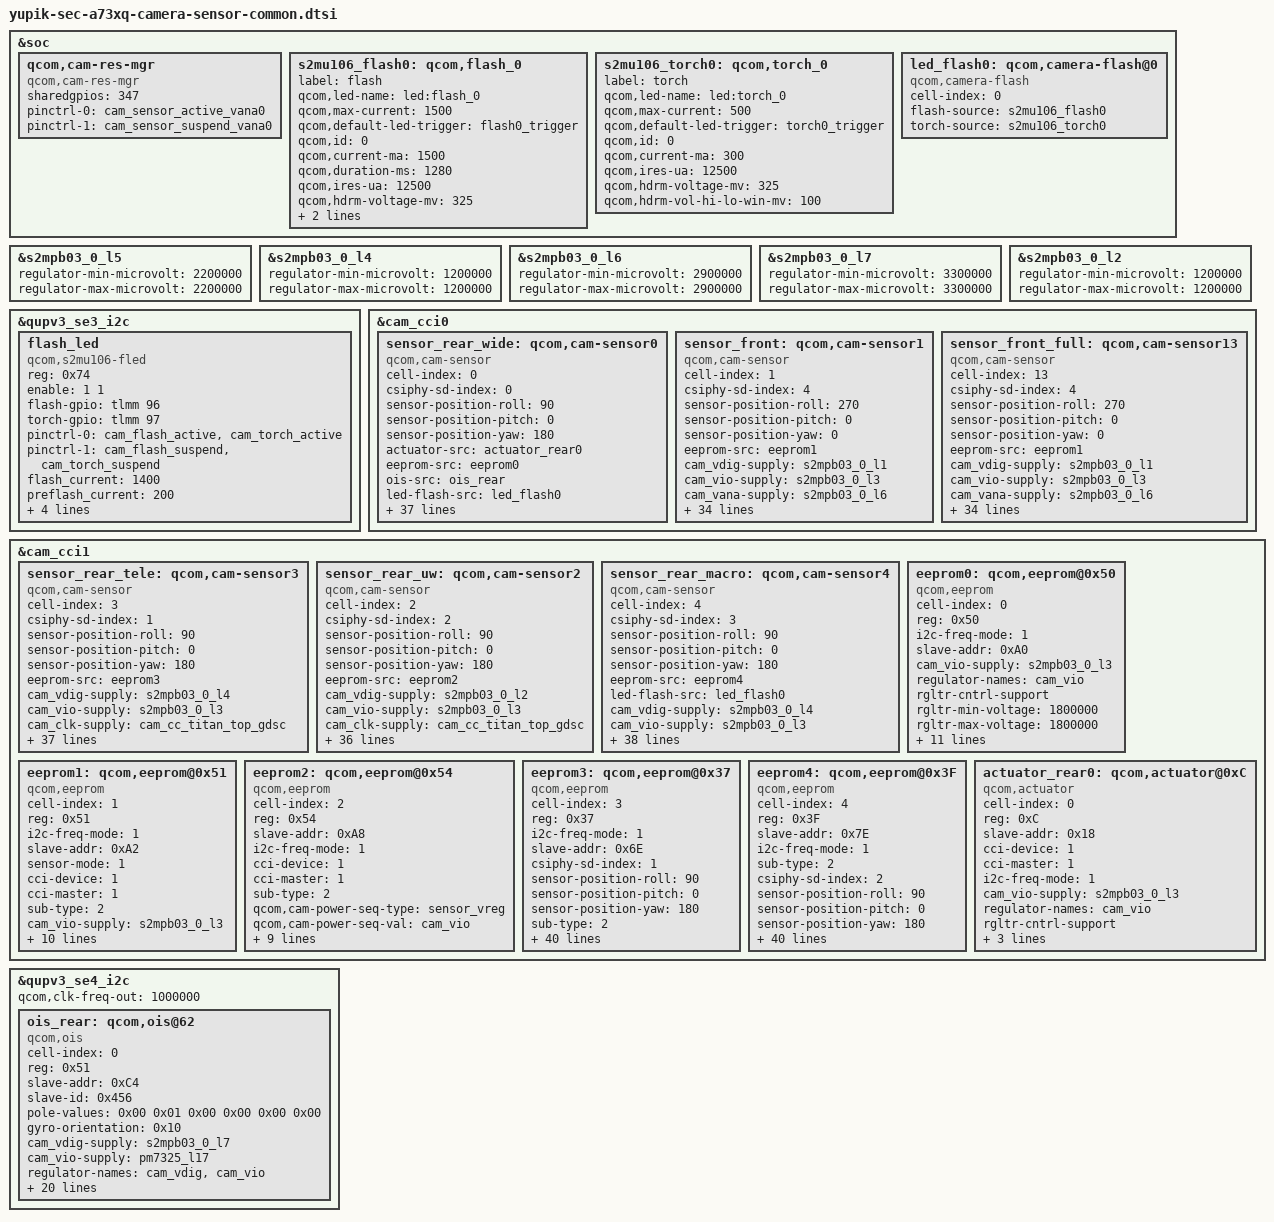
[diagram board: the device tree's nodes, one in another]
/*
 * Copyright (c) 2019, The Linux Foundation. All rights reserved.
 *
 * This program is free software; you can redistribute it and/or modify
 * it under the terms of the GNU General Public License version 2 and
 * only version 2 as published by the Free Software Foundation.
 *
 * This program is distributed in the hope that it will be useful,
 * but WITHOUT ANY WARRANTY; without even the implied warranty of
 * MERCHANTABILITY or FITNESS FOR A PARTICULAR PURPOSE.  See the
 * GNU General Public License for more details.
 */

#include <dt-bindings/clock/qcom,camcc-yupik.h>

#include <dt-bindings/regulator/qcom,rpmh-regulator-levels.h>
&soc {
	qcom,cam-res-mgr {
		compatible = "qcom,cam-res-mgr";
		sharedgpios = <347>;
		pinctrl-names = "cam_res_mgr_default", "cam_res_mgr_suspend";
		status = "ok";
		pinctrl-0 = <&cam_sensor_active_vana0>;
		pinctrl-1 = <&cam_sensor_suspend_vana0>;
    };
};

&s2mpb03_0_l5{
	regulator-min-microvolt = <2200000>;
	regulator-max-microvolt = <2200000>;
};

&s2mpb03_0_l4{
	regulator-min-microvolt = <1200000>;
	regulator-max-microvolt = <1200000>;
};

&s2mpb03_0_l6{
	regulator-min-microvolt = <2900000>;
	regulator-max-microvolt = <2900000>;
};

&s2mpb03_0_l7{
	regulator-min-microvolt = <3300000>;
	regulator-max-microvolt = <3300000>;
};

&s2mpb03_0_l2{
	regulator-min-microvolt = <1200000>;
	regulator-max-microvolt = <1200000>;
};

&soc {
	s2mu106_flash0: qcom,flash_0 {
		label = "flash";
		qcom,led-name = "led:flash_0";
		qcom,max-current = <1500>;
		qcom,default-led-trigger = "flash0_trigger";
		qcom,id = <0>;
		qcom,current-ma = <1500>;
		qcom,duration-ms = <1280>;
		qcom,ires-ua = <12500>;
		qcom,hdrm-voltage-mv = <325>;
		qcom,hdrm-vol-hi-lo-win-mv = <100>;
		qcom,record-current-ma = <200>;
	};

	s2mu106_torch0: qcom,torch_0 {
		label = "torch";
		qcom,led-name = "led:torch_0";
		qcom,max-current = <500>;
		qcom,default-led-trigger = "torch0_trigger";
		qcom,id = <0>;
		qcom,current-ma = <300>;
		qcom,ires-ua = <12500>;
		qcom,hdrm-voltage-mv = <325>;
		qcom,hdrm-vol-hi-lo-win-mv = <100>;
	};

        led_flash0: qcom,camera-flash@0 {
              cell-index = <0>;
              compatible = "qcom,camera-flash";
              flash-source = <&s2mu106_flash0>;
              torch-source = <&s2mu106_torch0>;
              status = "ok";
        };
};

&qupv3_se3_i2c {
	status = "ok";

	flash_led {
		reg = <0x74>;
		compatible = "qcom,s2mu106-fled";
		enable = <1 1>;
		flash-gpio = <&tlmm 96 0>;
		torch-gpio = <&tlmm 97 0>;
		pinctrl-names = "fled_default", "fled_suspend";
		pinctrl-0 = <&cam_flash_active &cam_torch_active>;
		pinctrl-1 = <&cam_flash_suspend &cam_torch_suspend>;
		flash_current = <1400>;
		preflash_current = <200>;
		torch_current = <300>;
		movie_current = <100>;
		factory_current = <300>;
		flashlight_current = <30 70 100 150 200>;
		status = "okay";
	};
};

&cam_cci0 {
// RCAM1 Wide 
	sensor_rear_wide: qcom,cam-sensor0 {
		cell-index = <0>;
		compatible = "qcom,cam-sensor";
		csiphy-sd-index = <0>;
		sensor-position-roll = <90>;
		sensor-position-pitch = <0>;
		sensor-position-yaw = <180>;
		actuator-src = <&actuator_rear0>;
		eeprom-src = <&eeprom0>;
		ois-src = <&ois_rear>;
		led-flash-src = <&led_flash0>;

		cam_vio-supply = <&s2mpb03_0_l3>; //CAM_VDDIO_1P8
		cam_vana-supply = <&s2mpb03_0_l5>; //RCAM1_AVDD_2P2
		cam_clk-supply = <&cam_cc_titan_top_gdsc>;
		regulator-names = "cam_vio", "cam_vana", "cam_clk" ;
		rgltr-cntrl-support;
		rgltr-min-voltage = <1800000 2200000 0>;
		rgltr-max-voltage = <1800000 2200000 0>;
		rgltr-load-current = <200000 5000 0>;
		gpio-no-mux = <0>;
		use-shared-clk;
		pinctrl-names = "cam_default", "cam_suspend";
		pinctrl-0 = <&cam_sensor_active_mclk0 &cam_sensor_active_rst0>;
		pinctrl-1 = <&cam_sensor_suspend_mclk0 &cam_sensor_suspend_rst0>;
		gpios = <&tlmm 64 0>,
			<&tlmm 20 0>,
			<&tlmm 11 0>;
		gpio-reset = <1>;
		gpio-vana  = <2>;
		gpio-req-tbl-num = <0 1 2>;
		gpio-req-tbl-flags = <1 0 0>;
		gpio-req-tbl-label = "CAMIF_MCLK0",
					"CAM_RESET0",
					"CAM_VANA0";
		sensor-mode = <0>;
		cci-master = <0>;
		status = "ok";
		clocks = <&camcc CAM_CC_MCLK0_CLK>;
		clock-names = "cam_clk";
		clock-cntl-level = "turbo";
		clock-rates = <24000000>;

		cam,isp = <0>;                  // 0 : INT , 1 : EXT , 2 : SOC
		cam,cal_memory = <2>;           // 0 : N , 1 : FROM , 2 : EEPROM , 3 : OTP
		cam,read_version = <1>;         // 0 : SYSFS , 1 : CAMON
		cam,core_voltage = <1>;         // 0 : N , 1 : Y
		cam,upgrade = <2>;              // 0 : N , 1 : SYSFS , 2 : CAMON
		cam,fw_write = <3>;             // 0 : N , 1 : OS , 2 : SD , 3 : ALL
		cam,fw_dump = <1>;              // 0 : N , 1 : Y
		cam,companion_chip = <0>;       // 0 : N , 1 : Y
		cam,ois = <1>;                  // 0 : N , 1 : Y
		cam,dual_open = <0>;            // 0 : N , 1 : Y
		cam,valid = <1>;                // 0 : N , 1 : Y
	};

	sensor_front: qcom,cam-sensor1 {
		cell-index = <1>;
		compatible = "qcom,cam-sensor";
		csiphy-sd-index = <4>;
		sensor-position-roll = <270>;
		sensor-position-pitch = <0>;
		sensor-position-yaw = <0>;
		eeprom-src = <&eeprom1>;

		cam_vdig-supply = <&s2mpb03_0_l1>;
		cam_vio-supply = <&s2mpb03_0_l3>;
		cam_vana-supply = <&s2mpb03_0_l6>;
		cam_clk-supply = <&cam_cc_titan_top_gdsc>;
		regulator-names = "cam_vdig", "cam_vio", "cam_vana", "cam_clk";
		rgltr-cntrl-support;
		rgltr-min-voltage = <1050000 1800000 2900000 0>;
		rgltr-max-voltage = <1050000 1800000 2900000 0>;
		rgltr-load-current = <200000 200000 5000 0>;
		gpio-no-mux = <0>;
		pinctrl-names = "cam_default", "cam_suspend";
		pinctrl-0 = <&cam_sensor_active_mclk3 &cam_sensor_active_rst3>;
		pinctrl-1 = <&cam_sensor_suspend_mclk3 &cam_sensor_suspend_rst3>;
		gpios = <&tlmm 68 0>,
			<&tlmm 79 0>;
		gpio-reset = <1>;
		gpio-req-tbl-num = <0 1>;
		gpio-req-tbl-flags = <1 0>;
		gpio-req-tbl-label = "CAMIF_MCLK4",
					"CAM_RESET4";
		sensor-mode = <0>;
		cci-device = <0>;
		cci-master = <1>;
		status = "ok";
		clocks = <&camcc CAM_CC_MCLK4_CLK>;
		clock-names = "cam_clk";
		clock-cntl-level = "turbo";
		clock-rates = <24000000>;

		cam,isp = <0>;                  // 0 : INT , 1 : EXT , 2 : SOC
		cam,cal_memory = <2>;           // 0 : N , 1 : FROM , 2 : EEPROM , 3 : OTP
		cam,read_version = <0>;         // 0 : SYSFS , 1 : CAMON
		cam,core_voltage = <0>;         // 0 : N , 1 : Y
		cam,upgrade = <0>;              // 0 : N , 1 : SYSFS , 2 : CAMON
		cam,fw_write = <0>;             // 0 : N , 1 : OS , 2 : SD , 3 : ALL
		cam,fw_dump = <0>;              // 0 : N , 1 : Y
		cam,companion_chip = <0>;       // 0 : N , 1 : Y
		cam,ois = <0>;                  // 0 : N , 1 : Y
		cam,dual_open = <0>;            // 0 : N , 1 : Y
		cam,valid = <1>;                // 0 : N , 1 : Y
	};
	
	sensor_front_full: qcom,cam-sensor13 {
		cell-index = <13>;
		compatible = "qcom,cam-sensor";
		csiphy-sd-index = <4>;
		sensor-position-roll = <270>;
		sensor-position-pitch = <0>;
		sensor-position-yaw = <0>;
		//actuator-src = <&actuator_front>;
		eeprom-src = <&eeprom1>;

		cam_vdig-supply = <&s2mpb03_0_l1>;
		cam_vio-supply = <&s2mpb03_0_l3>;
		cam_vana-supply = <&s2mpb03_0_l6>;
		cam_clk-supply = <&cam_cc_titan_top_gdsc>;
		regulator-names = "cam_vdig", "cam_vio", "cam_vana", "cam_clk";
		rgltr-cntrl-support;
		rgltr-min-voltage = <1050000 1800000 2900000 0>;
		rgltr-max-voltage = <1050000 1800000 2900000 0>;
		rgltr-load-current = <200000 200000 5000 0>;
		gpio-no-mux = <0>;
		pinctrl-names = "cam_default", "cam_suspend";
		pinctrl-0 = <&cam_sensor_active_mclk3 &cam_sensor_active_rst3>;
		pinctrl-1 = <&cam_sensor_suspend_mclk3 &cam_sensor_suspend_rst3>;
		gpios = <&tlmm 68 0>,
			<&tlmm 79 0>;
		gpio-reset = <1>;
		gpio-req-tbl-num = <0 1>;
		gpio-req-tbl-flags = <1 0>;
		gpio-req-tbl-label = "CAMIF_MCLK4",
					"CAM_RESET4";
		sensor-mode = <0>;
		cci-device = <0>;
		cci-master = <1>;
		status = "ok";
		clocks = <&camcc CAM_CC_MCLK4_CLK>;
		clock-names = "cam_clk";
		clock-cntl-level = "turbo";
		clock-rates = <24000000>;

		cam,isp = <0>;                  // 0 : INT , 1 : EXT , 2 : SOC
		cam,cal_memory = <2>;           // 0 : N , 1 : FROM , 2 : EEPROM , 3 : OTP
		cam,read_version = <0>;         // 0 : SYSFS , 1 : CAMON
		cam,core_voltage = <0>;         // 0 : N , 1 : Y
		cam,upgrade = <0>;              // 0 : N , 1 : SYSFS , 2 : CAMON
		cam,fw_write = <0>;             // 0 : N , 1 : OS , 2 : SD , 3 : ALL
		cam,fw_dump = <0>;              // 0 : N , 1 : Y
		cam,companion_chip = <0>;       // 0 : N , 1 : Y
		cam,ois = <0>;                  // 0 : N , 1 : Y
		cam,dual_open = <0>;            // 0 : N , 1 : Y
		cam,valid = <1>;                // 0 : N , 1 : Y
	};
};

&cam_cci1 {
	sensor_rear_tele: qcom,cam-sensor3 {
		cell-index = <3>;
		compatible = "qcom,cam-sensor";
		csiphy-sd-index = <1>;
		sensor-position-roll = <90>;
		sensor-position-pitch = <0>;
		sensor-position-yaw = <180>;
		eeprom-src = <&eeprom3>;

		cam_vdig-supply = <&s2mpb03_0_l4>;
		cam_vio-supply = <&s2mpb03_0_l3>;
		cam_clk-supply = <&cam_cc_titan_top_gdsc>;
		regulator-names = "cam_vdig", "cam_vio", "cam_clk";
		rgltr-cntrl-support;
		rgltr-min-voltage = <1200000 1800000 0>;
		rgltr-max-voltage = <1200000 1800000 0>;
		rgltr-load-current = <200000 200000  0>;
		gpio-no-mux = <0>;
		use-shared-clk;
		pinctrl-names = "cam_default", "cam_suspend";
		pinctrl-0 = <&cam_sensor_active_mclk1 &cam_sensor_active_rst1 &cam_sensor_active_vana1>;
		pinctrl-1 = <&cam_sensor_suspend_mclk1 &cam_sensor_suspend_rst1 &cam_sensor_suspend_vana1>;
		gpios = <&tlmm 65 0>,
			<&tlmm 21 0>,
			<&tlmm 14 0>;
		gpio-reset = <1>;
		gpio-vana  = <2>;
		gpio-req-tbl-num = <0 1 2>;
		gpio-req-tbl-flags = <1 0 0>;
		gpio-req-tbl-label = "CAMIF_MCLK1",
					"CAM_RESET1",
					"CAM_VANA1";	
		sensor-mode = <0>;
		cci-device = <1>;
		cci-master = <0>;
		status = "ok";
		clocks = <&camcc CAM_CC_MCLK1_CLK>;
		clock-names = "cam_clk";
		clock-cntl-level = "turbo";
		clock-rates = <24000000>;

		cam,isp = <0>;                  // 0 : INT , 1 : EXT , 2 : SOC
		cam,cal_memory = <2>;           // 0 : N , 1 : FROM , 2 : EEPROM , 3 : OTP
		cam,read_version = <0>;         // 0 : SYSFS , 1 : CAMON
		cam,core_voltage = <0>;         // 0 : N , 1 : Y
		cam,upgrade = <0>;              // 0 : N , 1 : SYSFS , 2 : CAMON
		cam,fw_write = <0>;             // 0 : N , 1 : OS , 2 : SD , 3 : ALL
		cam,fw_dump = <0>;              // 0 : N , 1 : Y
		cam,companion_chip = <0>;       // 0 : N , 1 : Y
		cam,ois = <0>;                  // 0 : N , 1 : Y
		cam,dual_open = <0>;            // 0 : N , 1 : Y
		cam,valid = <1>;                // 0 : N , 1 : Y
	};
	
	// RCAM2 12M UltraWide UW IMX258
	sensor_rear_uw: qcom,cam-sensor2 {
		cell-index = <2>;
		compatible = "qcom,cam-sensor";
		csiphy-sd-index = <2>;
		sensor-position-roll = <90>;
		sensor-position-pitch = <0>;
		sensor-position-yaw = <180>;
		eeprom-src = <&eeprom2>;

		cam_vdig-supply = <&s2mpb03_0_l2>;
		cam_vio-supply = <&s2mpb03_0_l3>;
		cam_clk-supply = <&cam_cc_titan_top_gdsc>;
		regulator-names = "cam_vdig", "cam_vio", "cam_clk";
		rgltr-cntrl-support;
		rgltr-min-voltage = <1200000 1800000 0>;
		rgltr-max-voltage = <1200000 1800000 0>;
		rgltr-load-current = <200000 200000 0>;
		gpio-no-mux = <0>;
		pinctrl-names = "cam_default", "cam_suspend";
		pinctrl-0 = <&cam_sensor_active_mclk2 &cam_sensor_active_rst2 &cam_sensor_active_vana2>;
		pinctrl-1 = <&cam_sensor_suspend_mclk2 &cam_sensor_suspend_rst2 &cam_sensor_suspend_vana2>;
		gpios = <&tlmm 66 0>,
			<&tlmm 77 0>,
			<&tlmm 15 0>;
		gpio-reset = <1>;
		gpio-vana  = <2>;
		gpio-req-tbl-num = <0 1 2>;
		gpio-req-tbl-flags = <1 0 0>;
		gpio-req-tbl-label = "CAMIF_MCLK2",
					"CAM_RESET2",
					"CAM_VANA2";

		sensor-mode = <0>;
		cci-device = <1>;
		cci-master = <0>;
		status = "ok";
		clocks = <&camcc CAM_CC_MCLK2_CLK>;
		clock-names = "cam_clk";
		clock-cntl-level = "turbo";
		clock-rates = <19200000>;

		cam,isp = <0>;                  // 0 : INT , 1 : EXT , 2 : SOC
		cam,cal_memory = <2>;           // 0 : N , 1 : FROM , 2 : EEPROM , 3 : OTP
		cam,read_version = <0>;         // 0 : SYSFS , 1 : CAMON
		cam,core_voltage = <0>;         // 0 : N , 1 : Y
		cam,upgrade = <0>;              // 0 : N , 1 : SYSFS , 2 : CAMON
		cam,fw_write = <0>;             // 0 : N , 1 : OS , 2 : SD , 3 : ALL
		cam,fw_dump = <0>;              // 0 : N , 1 : Y
		cam,companion_chip = <0>;       // 0 : N , 1 : Y
		cam,ois = <0>;                  // 0 : N , 1 : Y
		cam,dual_open = <0>;            // 0 : N , 1 : Y
		cam,valid = <1>;                // 0 : N , 1 : Y
	};
	
	sensor_rear_macro: qcom,cam-sensor4 {
		cell-index = <4>;
		compatible = "qcom,cam-sensor";
		csiphy-sd-index = <3>;
		sensor-position-roll = <90>;
		sensor-position-pitch = <0>;
		sensor-position-yaw = <180>;
		eeprom-src = <&eeprom4>;
		led-flash-src = <&led_flash0>;		

		cam_vdig-supply = <&s2mpb03_0_l4>;
		cam_vio-supply = <&s2mpb03_0_l3>;
		cam_clk-supply = <&cam_cc_titan_top_gdsc>;
		regulator-names = "cam_vdig", "cam_vio", "cam_clk";
		rgltr-cntrl-support;
		rgltr-min-voltage = <1200000 1800000 0>;
		rgltr-max-voltage = <1200000 1800000 0>;
		rgltr-load-current = <200000 200000  0>;
		gpio-no-mux = <0>;
		use-shared-clk;
		pinctrl-names = "cam_default", "cam_suspend";
		pinctrl-0 = <&cam_sensor_active_mclk4 &cam_sensor_active_rst4 &cam_sensor_active_vana1>;
		pinctrl-1 = <&cam_sensor_suspend_mclk4 &cam_sensor_suspend_rst4 &cam_sensor_suspend_vana1>;
		gpios = <&tlmm 67 0>,
			<&tlmm 78 0>,
			<&tlmm 14 0>;
		gpio-reset = <1>;
		gpio-vana  = <2>;
		gpio-req-tbl-num = <0 1 2>;
		gpio-req-tbl-flags = <1 0 0>;
		gpio-req-tbl-label = "CAMIF_MCLK3",
					"CAM_RESET3",
					"CAM_VANA1";	
		sensor-mode = <0>;
		cci-device = <1>;
		cci-master = <0>;
		status = "ok";
		clocks = <&camcc CAM_CC_MCLK3_CLK>;
		clock-names = "cam_clk";
		clock-cntl-level = "turbo";
		clock-rates = <24000000>;

		cam,isp = <0>;                  // 0 : INT , 1 : EXT , 2 : SOC
		cam,cal_memory = <2>;           // 0 : N , 1 : FROM , 2 : EEPROM , 3 : OTP
		cam,read_version = <0>;         // 0 : SYSFS , 1 : CAMON
		cam,core_voltage = <0>;         // 0 : N , 1 : Y
		cam,upgrade = <0>;              // 0 : N , 1 : SYSFS , 2 : CAMON
		cam,fw_write = <0>;             // 0 : N , 1 : OS , 2 : SD , 3 : ALL
		cam,fw_dump = <0>;              // 0 : N , 1 : Y
		cam,companion_chip = <0>;       // 0 : N , 1 : Y
		cam,ois = <0>;                  // 0 : N , 1 : Y
		cam,dual_open = <0>;            // 0 : N , 1 : Y
		cam,valid = <1>;                // 0 : N , 1 : Y
	};
	
    eeprom0: qcom,eeprom@0x50 {
		cell-index = <0>;
		reg = <0x50>;
		compatible = "qcom,eeprom";
		i2c-freq-mode = <1>;
		slave-addr = <0xA0>;

		cam_vio-supply = <&s2mpb03_0_l3>;
		regulator-names = "cam_vio";
		rgltr-cntrl-support;
		rgltr-min-voltage = <1800000>;
		rgltr-max-voltage = <1800000>;
		rgltr-load-current = <200000>;

		qcom,cam-power-seq-type = "sensor_vreg";
		qcom,cam-power-seq-val = "cam_vio";
		qcom,cam-power-seq-cfg-val = <1>;
		qcom,cam-power-seq-delay = <2>;
		
		sensor-mode = <0>;
		cci-device = <1>;
		cci-master = <1>;
		sub-type = <2>;
		
		sensor-position = <0>;
		gpio-no-mux = <0>;
	};

	eeprom1: qcom,eeprom@0x51 {
		cell-index = <1>;
		reg = <0x51>;
		compatible = "qcom,eeprom";
		i2c-freq-mode = <1>;
		slave-addr = <0xA2>;
		sensor-mode = <1>;
		cci-device = <1>;
		cci-master = <1>;
		sub-type = <2>;

		cam_vio-supply = <&s2mpb03_0_l3>;
		regulator-names = "cam_vio";
		rgltr-cntrl-support;
		rgltr-min-voltage = <1800000>;
		rgltr-max-voltage = <1800000>;
		rgltr-load-current = <200000>;

		qcom,cam-power-seq-type = "sensor_vreg";
		qcom,cam-power-seq-val = "cam_vio";
		qcom,cam-power-seq-cfg-val = <1>;
		qcom,cam-power-seq-delay = <2>;

		sensor-position = <1>;
	};

	eeprom2: qcom,eeprom@0x54 {
		cell-index = <2>;
		reg = <0x54>;
		slave-addr = <0xA8>;
		compatible = "qcom,eeprom";
		i2c-freq-mode = <1>;
		cci-device = <1>;
		cci-master = <1>;
		sub-type = <2>;
		
		qcom,cam-power-seq-type = "sensor_vreg";
		qcom,cam-power-seq-val = "cam_vio";
		qcom,cam-power-seq-cfg-val = <1>;
		qcom,cam-power-seq-delay = <2>;

		cam_vio-supply = <&s2mpb03_0_l3>;
		regulator-names = "cam_vio";
		rgltr-min-voltage = <1800000>;
		rgltr-max-voltage = <1800000>;
		rgltr-load-current = <200000>;

		sensor-position = <2>;
		rgltr-cntrl-support;
	};
	
	eeprom3: qcom,eeprom@0x37 {
		cell-index = <3>;
		reg = <0x37>;
		compatible = "qcom,eeprom";
		i2c-freq-mode = <1>;
		slave-addr = <0x6E>;

		csiphy-sd-index = <1>;
		sensor-position-roll = <90>;
		sensor-position-pitch = <0>;
		sensor-position-yaw = <180>;
		sub-type = <2>;

		cam_vdig-supply = <&s2mpb03_0_l4>;
		cam_vio-supply = <&s2mpb03_0_l3>;
		cam_clk-supply = <&cam_cc_titan_top_gdsc>;
		regulator-names = "cam_vdig", "cam_vio", "cam_clk";
		rgltr-cntrl-support;
		rgltr-min-voltage = <1200000 1800000 0>;
		rgltr-max-voltage = <1200000 1800000 0>;
		rgltr-load-current = <200000 200000  0>;
		gpio-no-mux = <0>;
		use-shared-clk;
		pinctrl-names = "cam_default", "cam_suspend";
		pinctrl-0 = <&cam_sensor_active_mclk1 &cam_sensor_active_rst1 &cam_sensor_active_vana1>;
		pinctrl-1 = <&cam_sensor_suspend_mclk1 &cam_sensor_suspend_rst1 &cam_sensor_suspend_vana1>;
		gpios = <&tlmm 65 0>,
			<&tlmm 21 0>,
			<&tlmm 14 0>;
		gpio-reset = <1>;
		gpio-vana  = <2>;
		gpio-req-tbl-num = <0 1 2>;
		gpio-req-tbl-flags = <1 0 0>;
		gpio-req-tbl-label = "CAMIF_MCLK1",
					"CAM_RESET1",
					"CAM_VANA1";

		sensor-mode = <0>;
		cci-device = <1>;
		cci-master = <0>;
		status = "ok";
		clocks = <&camcc CAM_CC_MCLK1_CLK>;
		clock-names = "cam_clk";
		clock-cntl-level = "turbo";
		clock-rates = <24000000>;

		cam,isp = <0>;					// 0 : INT , 1 : EXT , 2 : SOC
		cam,cal_memory = <2>;			// 0 : N , 1 : FROM , 2 : EEPROM , 3 : OTP
		cam,read_version = <1>;			// 0 : SYSFS , 1 : CAMON
		cam,core_voltage = <1>;			// 0 : N , 1 : Y
		cam,upgrade = <2>;				// 0 : N , 1 : SYSFS , 2 : CAMON
		cam,fw_write = <3>;				// 0 : N , 1 : OS , 2 : SD , 3 : ALL
		cam,fw_dump = <1>;				// 0 : N , 1 : Y
		cam,companion_chip = <0>;		// 0 : N , 1 : Y
		cam,ois = <0>;					// 0 : N , 1 : Y
		cam,dual_open = <0>;			// 0 : N , 1 : Y
		cam,valid = <1>;				// 0 : N , 1 : Y
	};
	
	eeprom4: qcom,eeprom@0x3F {
		cell-index = <4>;
		reg = <0x3F>;
		slave-addr = <0x7E>;
		compatible = "qcom,eeprom";
		i2c-freq-mode = <1>;
		sub-type = <2>;

		csiphy-sd-index = <2>;
		sensor-position-roll = <90>;
		sensor-position-pitch = <0>;
		sensor-position-yaw = <180>;

		cam_vdig-supply = <&s2mpb03_0_l4>;
		cam_vio-supply = <&s2mpb03_0_l3>;
		cam_clk-supply = <&cam_cc_titan_top_gdsc>;
		regulator-names = "cam_vdig", "cam_vio", "cam_clk";
		rgltr-cntrl-support;
		rgltr-min-voltage = <1200000 1800000 0>;
		rgltr-max-voltage = <1200000 1800000 0>;
		rgltr-load-current = <200000 200000  0>;

		gpio-no-mux = <0>;
		use-shared-clk;
		pinctrl-names = "cam_default", "cam_suspend";
		pinctrl-0 = <&cam_sensor_active_mclk4 &cam_sensor_active_rst4 &cam_sensor_active_vana1>;
		pinctrl-1 = <&cam_sensor_suspend_mclk4 &cam_sensor_suspend_rst4 &cam_sensor_suspend_vana1>;
		gpios = <&tlmm 67 0>,
			<&tlmm 78 0>,
			<&tlmm 14 0>;
		gpio-reset = <1>;
		gpio-vana  = <2>;
		gpio-req-tbl-num = <0 1 2>;
		gpio-req-tbl-flags = <1 0 0>;
		gpio-req-tbl-label = "CAMIF_MCLK3",
					"CAM_RESET3",
					"CAM_VANA1";	

		sensor-mode = <0>;
		cci-device = <1>;
		cci-master = <0>;
		status = "ok";
		clocks = <&camcc CAM_CC_MCLK3_CLK>;
		clock-names = "cam_clk";
		clock-cntl-level = "turbo";
		clock-rates = <24000000>;

		cam,isp = <0>;					// 0 : INT , 1 : EXT , 2 : SOC
		cam,cal_memory = <2>;			// 0 : N , 1 : FROM , 2 : EEPROM , 3 : OTP
		cam,read_version = <1>;			// 0 : SYSFS , 1 : CAMON
		cam,core_voltage = <1>;			// 0 : N , 1 : Y
		cam,upgrade = <2>;				// 0 : N , 1 : SYSFS , 2 : CAMON
		cam,fw_write = <3>;				// 0 : N , 1 : OS , 2 : SD , 3 : ALL
		cam,fw_dump = <1>;				// 0 : N , 1 : Y
		cam,companion_chip = <0>;		// 0 : N , 1 : Y
		cam,ois = <0>;					// 0 : N , 1 : Y
		cam,dual_open = <0>;			// 0 : N , 1 : Y
		cam,valid = <1>;				// 0 : N , 1 : Y
	};

	actuator_rear0: qcom,actuator@0xC {
		cell-index = <0>;
		reg = <0xC>;
		slave-addr = <0x18>;
		cci-device = <1>;
		cci-master = <1>;
		compatible = "qcom,actuator";
		i2c-freq-mode = <1>;
		cam_vio-supply = <&s2mpb03_0_l3>;
		regulator-names = "cam_vio";
		rgltr-cntrl-support;
		rgltr-min-voltage = <1800000>;
 		rgltr-max-voltage = <1800000>;
		rgltr-load-current = <200000>;
	};
};

&qupv3_se4_i2c { 
	status = "ok";
	qcom,clk-freq-out = <1000000>; /* 1MHz */
	ois_rear: qcom,ois@62  {
		compatible = "qcom,ois";
		cell-index = <0>;
		reg = <0x51>;
		slave-addr = <0xC4>;
		slave-id = <0x456>;
		pole-values = <0x00 0x01 0x00 0x00 0x00 0x00>;
		gyro-orientation = <0x10>;
		cam_vdig-supply = <&s2mpb03_0_l7>;//CAM_OIS_VDD_3P2
		cam_vio-supply = <&pm7325_l17>;//VDD_OIS_MCU_1P8
		regulator-names = "cam_vdig", "cam_vio";
		rgltr-cntrl-support;
		rgltr-min-voltage = <3300000 1800000>;
		rgltr-max-voltage = <3300000 1800000>;
		rgltr-load-current = <200000 200000>;

		qcom,cam-power-seq-type = "cam_vdig", "cam_vio", "cam_gpio_custom1", "cam_reset";
		qcom,cam-power-seq-cfg-val = <3200000 1800000 0 1>;
		qcom,cam-power-seq-delay = <1 1 1 10>;
		
		pinctrl-names = "cam_default", "cam_suspend";
		pinctrl-0 = <&mcu_reset_active &mcu_clk_active>; 
		pinctrl-1 = <&mcu_reset_suspend &mcu_clk_suspend>; 
		gpio-no-mux = <0>;
		gpios = <&tlmm 45 0>, // MCU_nRST
		        <&tlmm 11 0>, // MCU_VANA
		        <&tlmm 46 0>; // MCU_BOOT0_SWCLK

		gpio-reset = <0>;
		gpio-vana  = <1>;
		gpio-custom1 = <2>;
		gpio-req-tbl-num = <0 1 2>;
		gpio-req-tbl-flags = <0 0 0>;
		gpio-req-tbl-label = "MCU_RESET0", "MCU_VANA", "MCU_BOOT0";
		status = "ok";
	};
};


